VERSION ""

NS_ :

BS_:

BU_:

BO_ 3221225472 VECTOR__INDEPENDENT_SIG_MSG: 0 Vector__XXX
 SG_ motorEnable_Raw : 0|8@1+ (1,0) [0|255] "bool" Vector__XXX
 SG_ motor2PWM_Raw : 0|8@1+ (1,0) [0|255] "%" Vector__XXX
 SG_ motor1PWM_Raw : 0|8@1+ (1,0) [0|255] "%" Vector__XXX

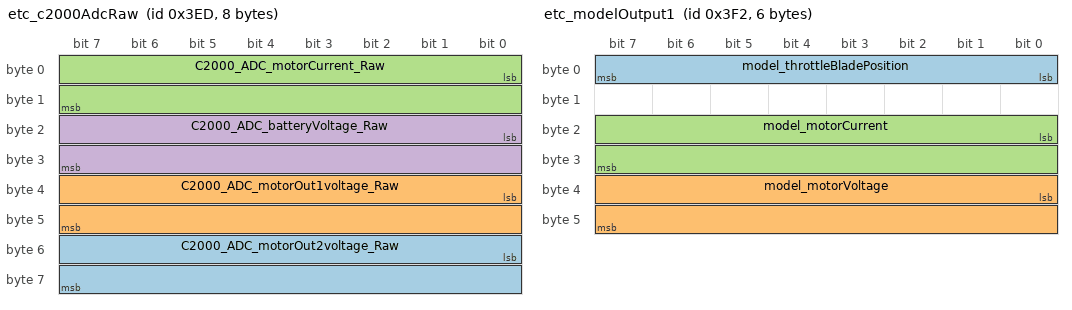
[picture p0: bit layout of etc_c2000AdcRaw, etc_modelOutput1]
BO_ 1005 etc_c2000AdcRaw: 8 Vector__XXX
 SG_ C2000_ADC_motorOut2voltage_Raw : 48|16@1+ (1,0) [0|0] "cnt" Vector__XXX
 SG_ C2000_ADC_motorOut1voltage_Raw : 32|16@1+ (1,0) [0|0] "cnt" Vector__XXX
 SG_ C2000_ADC_motorCurrent_Raw : 0|16@1+ (1,0) [0|0] "cnt" Vector__XXX
 SG_ C2000_ADC_batteryVoltage_Raw : 16|16@1+ (1,0) [0|0] "cnt" Vector__XXX

BO_ 1010 etc_modelOutput1: 6 Vector__XXX
 SG_ model_throttleBladePosition : 0|8@1+ (0.01,0) [0|2.55] "" Vector__XXX
 SG_ model_motorVoltage : 32|16@1- (0.001,0) [-32.768|32.767] "" Vector__XXX
 SG_ model_motorCurrent : 16|16@1- (0.001,0) [-32.768|32.767] "" Vector__XXX

BO_ 1004 etc_throttlePosition: 4 Vector__XXX
 SG_ etc_throttlePosition2 : 16|16@1+ (0.01,0) [0|655.35] "" Vector__XXX
 SG_ etc_throttlePosition1 : 0|16@1+ (0.01,0) [0|655.35] "" Vector__XXX

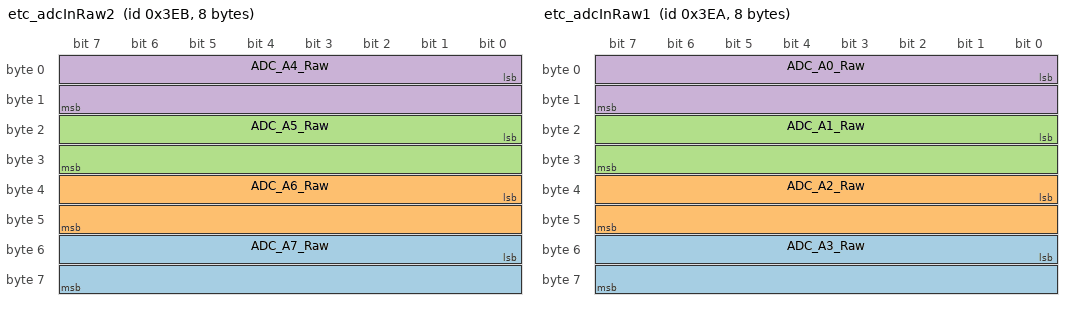
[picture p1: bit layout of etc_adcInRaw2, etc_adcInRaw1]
BO_ 1003 etc_adcInRaw2: 8 Vector__XXX
 SG_ ADC_A7_Raw : 48|16@1+ (1,0) [0|0] "cnt" Vector__XXX
 SG_ ADC_A6_Raw : 32|16@1+ (1,0) [0|0] "cnt" Vector__XXX
 SG_ ADC_A5_Raw : 16|16@1+ (1,0) [0|0] "cnt" Vector__XXX
 SG_ ADC_A4_Raw : 0|16@1+ (1,0) [0|0] "cnt" Vector__XXX

BO_ 1002 etc_adcInRaw1: 8 Vector__XXX
 SG_ ADC_A3_Raw : 48|16@1+ (1,0) [0|0] "cnt" Vector__XXX
 SG_ ADC_A2_Raw : 32|16@1+ (1,0) [0|0] "cnt" Vector__XXX
 SG_ ADC_A1_Raw : 16|16@1+ (1,0) [0|0] "cnt" Vector__XXX
 SG_ ADC_A0_Raw : 0|16@1+ (1,0) [0|0] "cnt" Vector__XXX

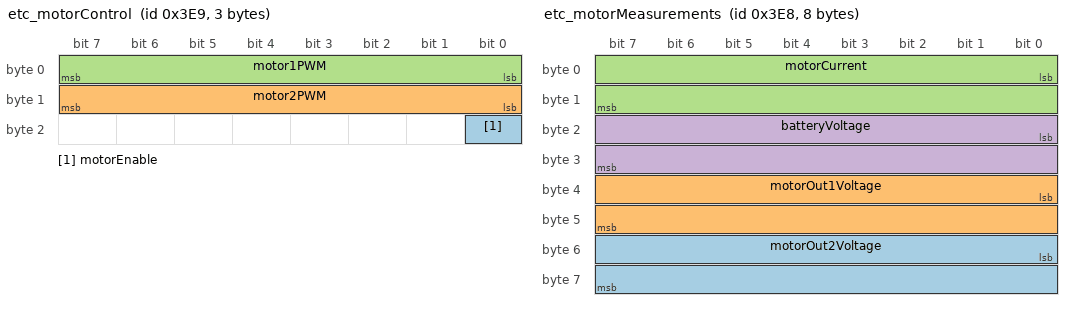
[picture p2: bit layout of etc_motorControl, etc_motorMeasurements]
BO_ 1001 etc_motorControl: 3 Vector__XXX
 SG_ motorEnable : 16|1@1+ (1,0) [0|1] "bool" Vector__XXX
 SG_ motor2PWM : 8|8@1+ (1,0) [0|255] "%" Vector__XXX
 SG_ motor1PWM : 0|8@1+ (1,0) [0|255] "%" Vector__XXX

BO_ 1000 etc_motorMeasurements: 8 Vector__XXX
 SG_ motorOut2Voltage : 48|16@1- (0.001,0) [-32.768|32.767] "V" Vector__XXX
 SG_ motorOut1Voltage : 32|16@1- (0.001,0) [-32.768|32.767] "V" Vector__XXX
 SG_ motorCurrent : 0|16@1- (0.001,0) [-32.768|32.767] "A" Vector__XXX
 SG_ batteryVoltage : 16|16@1- (0.001,0) [-32.768|32.767] "V" Vector__XXX

CM_ BO_ 3221225472 "This is a message for not used signals, created by Vector CANdb++ DBC OLE DB Provider.";
